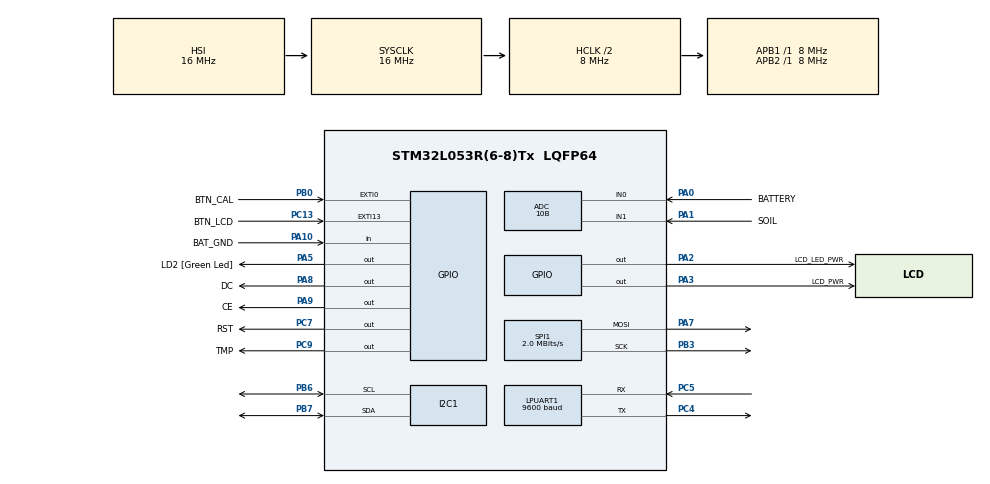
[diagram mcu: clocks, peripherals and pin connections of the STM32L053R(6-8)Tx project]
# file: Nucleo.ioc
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ADC.ClockPrescaler=ADC_CLOCK_ASYNC_DIV1
ADC.ContinuousConvMode=DISABLE
ADC.DMAContinuousRequests=DISABLE
ADC.DataAlign=ADC_DATAALIGN_RIGHT
ADC.DiscontinuousConvMode=DISABLE
ADC.EOCSelection=ADC_EOC_SINGLE_CONV
ADC.EnableAnalogWatchDog=false
ADC.ExternalTrigConv=ADC_SOFTWARE_START
ADC.ExternalTrigConvEdge=ADC_EXTERNALTRIGCONVEDGE_NONE
ADC.LowPowerAutoPowerOff=DISABLE
ADC.LowPowerAutoWait=DISABLE
ADC.LowPowerFrequencyMode=DISABLE
ADC.Overrun=ADC_OVR_DATA_PRESERVED
ADC.OversamplingMode=DISABLE
ADC.Resolution=ADC_RESOLUTION_10B
ADC.SamplingTime=ADC_SAMPLETIME_160CYCLES_5
ADC.ScanConvMode=ADC_SCAN_DIRECTION_FORWARD
I2C1.OwnAddress=72
I2C1.Timing=0x2000090E
LPUART1.BaudRate=9600
LPUART1.Parity=UART_PARITY_NONE
LPUART1.WordLength=UART_WORDLENGTH_8B
Mcu.Family=STM32L0
Mcu.Name=STM32L053R(6-8)Tx
Mcu.Package=LQFP64
NVIC.AES_RNG_LPUART1_IRQn=true\:0\:0\:false\:false\:true
NVIC.EXTI0_1_IRQn=true\:1\:0\:true\:false\:true
NVIC.EXTI4_15_IRQn=true\:1\:0\:true\:false\:true
NVIC.RTC_IRQn=true\:3\:0\:true\:false\:true
NVIC.TIM22_IRQn=true\:3\:0\:true\:false\:true
NVIC.TIM6_DAC_IRQn=true\:3\:0\:true\:false\:true
PA0.GPIO_Label=BATTERY
PA0.Mode=IN0
PA0.Signal=ADC_IN0
PA1.GPIO_Label=SOIL
PA1.Mode=IN1
PA1.Signal=ADC_IN1
PA10.GPIO_Label=BAT_GND
PA10.Signal=GPIO_Input
PA13.GPIO_Label=TMS
PA13.Signal=SYS_SWDIO
PA14.GPIO_Label=TCK
PA14.Signal=SYS_SWCLK
PA2.GPIO_Label=LCD_LED_PWR
PA2.PinState=GPIO_PIN_SET
PA2.Signal=GPIO_Output
PA3.GPIO_Label=LCD_PWR
PA3.PinState=GPIO_PIN_SET
PA3.Signal=GPIO_Output
PA5.GPIO_Label=LD2 [Green Led]
PA5.Signal=GPIO_Output
PA7.Mode=TX_Only_Simplex_Unidirect_Master
PA7.Signal=SPI1_MOSI
PA8.GPIO_Label=DC
PA8.Signal=GPIO_Output
PA9.GPIO_Label=CE
PA9.Signal=GPIO_Output
PB0.GPIO_Label=BTN_CAL
PB0.GPIO_ModeDefaultEXTI=GPIO_MODE_IT_FALLING
PB0.Signal=GPXTI0
PB3.Mode=TX_Only_Simplex_Unidirect_Master
PB3.Signal=SPI1_SCK
PB6.Mode=I2C
PB6.Signal=I2C1_SCL
PB7.Mode=I2C
PB7.Signal=I2C1_SDA
PC13.GPIO_Label=BTN_LCD
PC13.GPIO_ModeDefaultEXTI=GPIO_MODE_IT_FALLING
PC13.Signal=GPXTI13
PC14-OSC32_IN.Mode=LSE-External-Oscillator
PC14-OSC32_IN.Signal=RCC_OSC32_IN
PC15-OSC32_OUT.Mode=LSE-External-Oscillator
PC15-OSC32_OUT.Signal=RCC_OSC32_OUT
PC4.Mode=Asynchronous
PC4.Signal=LPUART1_TX
PC5.Mode=Asynchronous
PC5.Signal=LPUART1_RX
PC7.GPIO_Label=RST
PC7.Signal=GPIO_Output
PC9.GPIO_Label=TMP
PC9.GPIO_Speed=GPIO_SPEED_FREQ_MEDIUM
PC9.PinState=GPIO_PIN_SET
PC9.Signal=GPIO_Output
PH0-OSC_IN.Signal=RCC_OSC_IN
PH1-OSC_OUT.Signal=RCC_OSC_OUT
ProjectManager.HeapSize=0x200
ProjectManager.StackSize=0x400
ProjectManager.TargetToolchain=SW4STM32
RCC.AHBCLKDivider=RCC_SYSCLK_DIV2
RCC.AHBFreq_Value=8000000
RCC.APB1Freq_Value=8000000
RCC.APB1TimFreq_Value=8000000
RCC.APB2Freq_Value=8000000
RCC.APB2TimFreq_Value=8000000
RCC.HCLKFreq_Value=8000000
RCC.HSE_VALUE=8000000
RCC.HSI16_VALUE=16000000
RCC.HSI48_VALUE=48000000
RCC.HSI_VALUE=16000000
RCC.LptimClockSelection=RCC_LPTIM1CLKSOURCE_LSE
RCC.Lpuart1ClockSelection=RCC_LPUART1CLKSOURCE_LSE
RCC.MSI_VALUE=2097000
RCC.RTCClockSelection=RCC_RTCCLKSOURCE_LSE
RCC.RTCClockSelectionVirtual=RCC_RTCCLKSOURCE_LSE
RCC.SYSCLKFreq_VALUE=16000000
RCC.SYSCLKSource=RCC_SYSCLKSOURCE_HSI
RCC.VCOOutputFreq_Value=48000000
RTC.WakeUpClock-WakeUp=RTC_WAKEUPCLOCK_CK_SPRE_16BITS
RTC.WakeUpCounter-WakeUp=30
SPI1.BaudRatePrescaler=SPI_BAUDRATEPRESCALER_4
SPI1.CalculateBaudRate=2.0 MBits/s
SPI1.Direction=SPI_DIRECTION_2LINES
SPI1.Mode=SPI_MODE_MASTER
SPI1.VirtualType=VM_MASTER
TIM2.Period=2000
TIM2.Prescaler=7
TIM22.Period=49
TIM22.Prescaler=8
TIM6.Period=9999
TIM6.Prescaler=799
VP_RTC_VS_RTC_Activate.Mode=RTC_Enabled
VP_RTC_VS_RTC_Calendar.Mode=RTC_Calendar
VP_RTC_VS_RTC_WakeUp_intern.Mode=WakeUp
VP_TIM22_VS_ClockSourceINT.Mode=Internal
VP_TIM2_VS_ClockSourceINT.Mode=Internal
VP_TIM6_VS_ClockSourceINT.Mode=Enable_Timer
board=NUCLEO-L053R8

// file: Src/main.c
/**
  ******************************************************************************
  * File Name          : main.c
  * Description        : Main program body
  ******************************************************************************
  ** This notice applies to any and all portions of this file
  * that are not between comment pairs USER CODE BEGIN and
  * USER CODE END. Other portions of this file, whether
  * inserted by the user or by software development tools
  * are owned by their respective copyright owners.
  *
  * COPYRIGHT(c) 2018 STMicroelectronics
  *
  * Redistribution and use in source and binary forms, with or without modification,
  * are permitted provided that the following conditions are met:
  *   1. Redistributions of source code must retain the above copyright notice,
  *      this list of conditions and the following disclaimer.
  *   2. Redistributions in binary form must reproduce the above copyright notice,
  *      this list of conditions and the following disclaimer in the documentation
  *      and/or other materials provided with the distribution.
  *   3. Neither the name of STMicroelectronics nor the names of its contributors
  *      may be used to endorse or promote products derived from this software
  *      without specific prior written permission.
  *
  * THIS SOFTWARE IS PROVIDED BY THE COPYRIGHT HOLDERS AND CONTRIBUTORS "AS IS"
  * AND ANY EXPRESS OR IMPLIED WARRANTIES, INCLUDING, BUT NOT LIMITED TO, THE
  * IMPLIED WARRANTIES OF MERCHANTABILITY AND FITNESS FOR A PARTICULAR PURPOSE ARE
  * DISCLAIMED. IN NO EVENT SHALL THE COPYRIGHT HOLDER OR CONTRIBUTORS BE LIABLE
  * FOR ANY DIRECT, INDIRECT, INCIDENTAL, SPECIAL, EXEMPLARY, OR CONSEQUENTIAL
  * DAMAGES (INCLUDING, BUT NOT LIMITED TO, PROCUREMENT OF SUBSTITUTE GOODS OR
  * SERVICES; LOSS OF USE, DATA, OR PROFITS; OR BUSINESS INTERRUPTION) HOWEVER
  * CAUSED AND ON ANY THEORY OF LIABILITY, WHETHER IN CONTRACT, STRICT LIABILITY,
  * OR TORT (INCLUDING NEGLIGENCE OR OTHERWISE) ARISING IN ANY WAY OUT OF THE USE
  * OF THIS SOFTWARE, EVEN IF ADVISED OF THE POSSIBILITY OF SUCH DAMAGE.
  *
  ******************************************************************************
  */
#include "main.h"
#include "stm32l0xx_hal.h"
#include "adc.h"
#include "i2c.h"
#include "usart.h"
#include "rtc.h"
#include "spi.h"
#include "tim.h"
#include "gpio.h"

/* USER CODE BEGIN Includes */
#include "lcd.h"
#include "BV1750FVI.h"
#include "am2302.h"
#include "mbtask.h"
/* USER CODE END Includes */

/* USER CODE BEGIN PV */
/* Private variables ---------------------------------------------------------*/
UART_HandleTypeDef UartHandle;
/* USER CODE END PV */

void SystemClock_Config(void);

/* USER CODE BEGIN PFP */
/* Private function prototypes -----------------------------------------------*/

/* USER CODE END PFP */

int main(void)
{

  /* MCU Configuration----------------------------------------------------------*/

  /* Reset of all peripherals, Initializes the Flash interface and the Systick. */
  HAL_Init();

  /* Configure the system clock */
  SystemClock_Config();

  /* Initialize all configured peripherals */
  MX_GPIO_Init();
  MX_LPUART1_UART_Init();
  MX_RTC_Init();
  MX_SPI1_Init();
  MX_I2C1_Init();
  MX_ADC_Init();
  MX_TIM6_Init();
  MX_TIM2_Init();
  MX_TIM22_Init();

  /* USER CODE BEGIN 2 */
  LCD_init();
  am2302_Init();
  BV_Init();
  SoilInit();
  HAL_GPIO_WritePin(LD2_GPIO_Port,LD2_Pin,GPIO_PIN_SET);

  /* USER CODE END 2 */

  /* Infinite loop */
  while (1)
  {

  /* USER CODE BEGIN 3 */
	  ModbusRTUTask("asd");
  }
  /* USER CODE END 3 */

}

/** System Clock Configuration
*/
void SystemClock_Config(void)
{

  RCC_OscInitTypeDef RCC_OscInitStruct;
  RCC_ClkInitTypeDef RCC_ClkInitStruct;
  RCC_PeriphCLKInitTypeDef PeriphClkInit;

    /**Configure the main internal regulator output voltage
    */
  __HAL_PWR_VOLTAGESCALING_CONFIG(PWR_REGULATOR_VOLTAGE_SCALE1);

    /**Configure LSE Drive Capability
    */
  __HAL_RCC_LSEDRIVE_CONFIG(RCC_LSEDRIVE_LOW);

    /**Initializes the CPU, AHB and APB busses clocks
    */
  RCC_OscInitStruct.OscillatorType = RCC_OSCILLATORTYPE_HSI|RCC_OSCILLATORTYPE_LSE;
  RCC_OscInitStruct.LSEState = RCC_LSE_ON;
  RCC_OscInitStruct.HSIState = RCC_HSI_ON;
  RCC_OscInitStruct.HSICalibrationValue = 16;
  RCC_OscInitStruct.PLL.PLLState = RCC_PLL_NONE;
  if (HAL_RCC_OscConfig(&RCC_OscInitStruct) != HAL_OK)
  {
    _Error_Handler(__FILE__, __LINE__);
  }

    /**Initializes the CPU, AHB and APB busses clocks
    */
  RCC_ClkInitStruct.ClockType = RCC_CLOCKTYPE_HCLK|RCC_CLOCKTYPE_SYSCLK
                              |RCC_CLOCKTYPE_PCLK1|RCC_CLOCKTYPE_PCLK2;
  RCC_ClkInitStruct.SYSCLKSource = RCC_SYSCLKSOURCE_HSI;
  RCC_ClkInitStruct.AHBCLKDivider = RCC_SYSCLK_DIV2;
  RCC_ClkInitStruct.APB1CLKDivider = RCC_HCLK_DIV1;
  RCC_ClkInitStruct.APB2CLKDivider = RCC_HCLK_DIV1;

  if (HAL_RCC_ClockConfig(&RCC_ClkInitStruct, FLASH_LATENCY_0) != HAL_OK)
  {
    _Error_Handler(__FILE__, __LINE__);
  }

  PeriphClkInit.PeriphClockSelection = RCC_PERIPHCLK_LPUART1|RCC_PERIPHCLK_I2C1
                              |RCC_PERIPHCLK_RTC;
  PeriphClkInit.Lpuart1ClockSelection = RCC_LPUART1CLKSOURCE_LSE;
  PeriphClkInit.I2c1ClockSelection = RCC_I2C1CLKSOURCE_PCLK1;
  PeriphClkInit.RTCClockSelection = RCC_RTCCLKSOURCE_LSE;
  if (HAL_RCCEx_PeriphCLKConfig(&PeriphClkInit) != HAL_OK)
  {
    _Error_Handler(__FILE__, __LINE__);
  }

    /**Configure the Systick interrupt time
    */
  HAL_SYSTICK_Config(HAL_RCC_GetHCLKFreq()/1000);

    /**Configure the Systick
    */
  HAL_SYSTICK_CLKSourceConfig(SYSTICK_CLKSOURCE_HCLK);

  /* SysTick_IRQn interrupt configuration */
  HAL_NVIC_SetPriority(SysTick_IRQn, 0, 0);
}

void _Error_Handler(char * file, int line)
{
  while(1)
  {
  }
}

/************************ (C) COPYRIGHT STMicroelectronics *****END OF FILE****/
